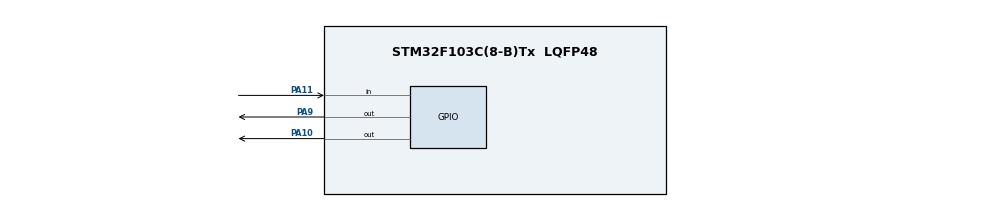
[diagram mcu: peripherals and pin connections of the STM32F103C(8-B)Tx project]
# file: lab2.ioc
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FREERTOS.Tasks01=defaultTask,16,128,StartDefaultTask,Default,NULL,Dynamic,NULL,NULL;BlinkLed1,8,128,StartBlinkLed1,Default,NULL,Dynamic,NULL,NULL;LedBtn,8,128,StartLedBtn,Default,NULL,Dynamic,NULL,NULL
Mcu.Family=STM32F1
Mcu.Name=STM32F103C(8-B)Tx
Mcu.Package=LQFP48
NVIC.PriorityGroup=NVIC_PRIORITYGROUP_4
PA10.Signal=GPIO_Output
PA11.Signal=GPIO_Input
PA13.Mode=Serial_Wire
PA13.Signal=SYS_JTMS-SWDIO
PA14.Mode=Serial_Wire
PA14.Signal=SYS_JTCK-SWCLK
PA9.Signal=GPIO_Output
PC14-OSC32_IN.Mode=LSE-External-Clock-Source
PC14-OSC32_IN.Signal=RCC_OSC32_IN
PC15-OSC32_OUT.Mode=LSE-External-Clock-Source
PC15-OSC32_OUT.Signal=RCC_OSC32_OUT
PD0-OSC_IN.Mode=HSE-External-Clock-Source
PD0-OSC_IN.Signal=RCC_OSC_IN
PD1-OSC_OUT.Mode=HSE-External-Clock-Source
PD1-OSC_OUT.Signal=RCC_OSC_OUT
ProjectManager.HeapSize=0x200
ProjectManager.StackSize=0x400
ProjectManager.TargetToolchain=STM32CubeIDE
RCC.APB1Freq_Value=8000000
RCC.APB2Freq_Value=8000000
VP_FREERTOS_VS_CMSIS_V2.Mode=CMSIS_V2
board=custom

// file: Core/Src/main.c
/* USER CODE BEGIN Header */
/**
  ******************************************************************************
  * @file           : main.c
  * @brief          : LAB work 2 for KPI RTOS course
  * Variant 2, task:
  * freeRtos task1: led 1 blinking freq 2Hz, pulse time 100ms,
  * freeRtos task2: led 2 displays button state
  * CONNECTIONS
  * PA9 - led2
  * PA10 - led1
  * PA11 - button
  ******************************************************************************
  * @attention
  *
  * Copyright (c) 2026 STMicroelectronics.
  * All rights reserved.
  *
  * This software is licensed under terms that can be found in the LICENSE file
  * in the root directory of this software component.
  * If no LICENSE file comes with this software, it is provided AS-IS.
  *
  ******************************************************************************
  */
/* USER CODE END Header */
#include "main.h"
#include "cmsis_os.h"

/* Definitions for BlinkLed1 */
osThreadId_t BlinkLed1Handle;
const osThreadAttr_t BlinkLed1_attributes = {
  .name = "BlinkLed1",
  .stack_size = 128 * 4,
  .priority = (osPriority_t) osPriorityLow,
};
/* Definitions for LedBtn */
osThreadId_t LedBtnHandle;
const osThreadAttr_t LedBtn_attributes = {
  .name = "LedBtn",
  .stack_size = 128 * 4,
  .priority = (osPriority_t) osPriorityLow,
};

void SystemClock_Config(void);
static void MX_GPIO_Init(void);
void StartBlinkLed1(void *argument);
void StartLedBtn(void *argument);

int main(void)
{

  /* MCU Configuration--------------------------------------------------------*/

  /* Reset of all peripherals, Initializes the Flash interface and the Systick. */
  HAL_Init();

  /* Configure the system clock */
  SystemClock_Config();

  /* Initialize all configured peripherals */
  MX_GPIO_Init();

  /* Init scheduler */
  osKernelInitialize();

  /* Create the thread(s) */

  /* creation of BlinkLed1 */
  BlinkLed1Handle = osThreadNew(StartBlinkLed1, NULL, &BlinkLed1_attributes);

  /* creation of LedBtn */
  LedBtnHandle = osThreadNew(StartLedBtn, NULL, &LedBtn_attributes);

  /* Start scheduler */
  osKernelStart();

  /* We should never get here as control is now taken by the scheduler */

  /* Infinite loop */
  /* USER CODE BEGIN WHILE */
  while (1)
  {
//	  HAL_GPIO_WritePin(GPIOA, GPIO_PIN_9, GPIO_PIN_SET);
//	  HAL_Delay(100); // ~50 Гц
//
//	  if (HAL_GPIO_ReadPin(GPIOA, GPIO_PIN_8) == GPIO_PIN_SET) {
//		  HAL_GPIO_WritePin(GPIOA, GPIO_PIN_10, GPIO_PIN_RESET);
//	  } else {
//		  HAL_GPIO_TogglePin(GPIOA, GPIO_PIN_10);
//		  HAL_Delay(100); // ~50 Гц
//	  }
    /* USER CODE END WHILE */

  }
}

void SystemClock_Config(void)
{
  RCC_OscInitTypeDef RCC_OscInitStruct = {0};
  RCC_ClkInitTypeDef RCC_ClkInitStruct = {0};

  /** Initializes the RCC Oscillators according to the specified parameters
  * in the RCC_OscInitTypeDef structure.
  */
  RCC_OscInitStruct.OscillatorType = RCC_OSCILLATORTYPE_HSI;
  RCC_OscInitStruct.HSIState = RCC_HSI_ON;
  RCC_OscInitStruct.HSICalibrationValue = RCC_HSICALIBRATION_DEFAULT;
  RCC_OscInitStruct.PLL.PLLState = RCC_PLL_NONE;
  if (HAL_RCC_OscConfig(&RCC_OscInitStruct) != HAL_OK)
  {
    Error_Handler();
  }

  /** Initializes the CPU, AHB and APB buses clocks
  */
  RCC_ClkInitStruct.ClockType = RCC_CLOCKTYPE_HCLK|RCC_CLOCKTYPE_SYSCLK
                              |RCC_CLOCKTYPE_PCLK1|RCC_CLOCKTYPE_PCLK2;
  RCC_ClkInitStruct.SYSCLKSource = RCC_SYSCLKSOURCE_HSI;
  RCC_ClkInitStruct.AHBCLKDivider = RCC_SYSCLK_DIV1;
  RCC_ClkInitStruct.APB1CLKDivider = RCC_HCLK_DIV1;
  RCC_ClkInitStruct.APB2CLKDivider = RCC_HCLK_DIV1;

  if (HAL_RCC_ClockConfig(&RCC_ClkInitStruct, FLASH_LATENCY_0) != HAL_OK)
  {
    Error_Handler();
  }
}

static void MX_GPIO_Init(void)
{
  GPIO_InitTypeDef GPIO_InitStruct = {0};

  /* GPIO Ports Clock Enable */
  __HAL_RCC_GPIOC_CLK_ENABLE();
  __HAL_RCC_GPIOD_CLK_ENABLE();
  __HAL_RCC_GPIOA_CLK_ENABLE();

  /*Configure GPIO pin Output Level */
  HAL_GPIO_WritePin(GPIOA, GPIO_PIN_9|GPIO_PIN_10, GPIO_PIN_RESET);

  /*Configure GPIO pins : PA9 PA10 */
  GPIO_InitStruct.Pin = GPIO_PIN_9|GPIO_PIN_10;
  GPIO_InitStruct.Mode = GPIO_MODE_OUTPUT_PP;
  GPIO_InitStruct.Pull = GPIO_NOPULL;
  GPIO_InitStruct.Speed = GPIO_SPEED_FREQ_LOW;
  HAL_GPIO_Init(GPIOA, &GPIO_InitStruct);

  /*Configure GPIO pin : PA11 */
  GPIO_InitStruct.Pin = GPIO_PIN_11;
  GPIO_InitStruct.Mode = GPIO_MODE_INPUT;
  GPIO_InitStruct.Pull = GPIO_PULLDOWN;
  HAL_GPIO_Init(GPIOA, &GPIO_InitStruct);

}

void StartBlinkLed1(void *argument)
{
  /* USER CODE BEGIN StartBlinkLed1 */
  /* Infinite loop */
  for(;;)
  {
	  HAL_GPIO_WritePin(GPIOA, GPIO_PIN_10, GPIO_PIN_SET);
	  osDelay(100);
	  HAL_GPIO_WritePin(GPIOA, GPIO_PIN_10, GPIO_PIN_RESET);
	  osDelay(400);
  }
  /* USER CODE END StartBlinkLed1 */
}

void StartLedBtn(void *argument)
{
  /* USER CODE BEGIN StartLedBtn */
  /* Infinite loop */
  for(;;)
  {
	  HAL_GPIO_WritePin(GPIOA, GPIO_PIN_9, HAL_GPIO_ReadPin(GPIOA, GPIO_PIN_11));
  }
  /* USER CODE END StartLedBtn */
}

void Error_Handler(void)
{
  __disable_irq();
  while (1)
  {
  }
}
